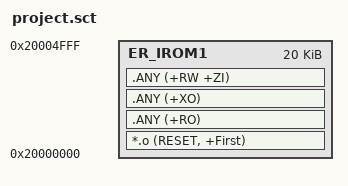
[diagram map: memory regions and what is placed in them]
; *************************************************************
; *** Scatter-Loading Description File generated by uVision ***
; *************************************************************

LR_IROM1 0x20000000 0x00005000  {    ; load region size_region
  ER_IROM1 0x20000000 0x00005000  {  ; load address = execution address
   *.o (RESET, +First)
   .ANY (+RO)
   .ANY (+XO)
   .ANY (+RW +ZI)
  }
}

